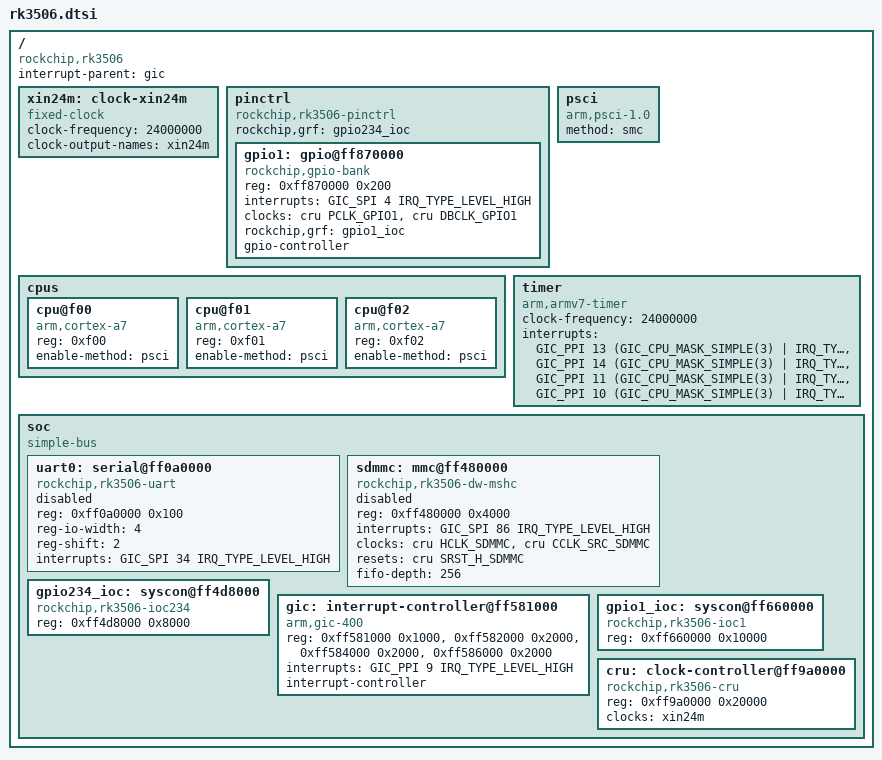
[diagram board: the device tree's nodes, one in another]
// SPDX-License-Identifier: (GPL-2.0+ OR MIT)
/*
 * Rockchip RK3506, Cortex-A7 application processor.
 * Register and interrupt assignments from the Rockchip RK3506 BSP and
 * the RK3506 device tree by Jonas Karlman (linux-rockchip 7e4c7f871924).
 */

#include <dt-bindings/clock/rockchip,rk3506-cru.h>
#include <dt-bindings/interrupt-controller/arm-gic.h>
#include <dt-bindings/reset/rockchip,rk3506-cru.h>

/ {
	#address-cells = <1>;
	#size-cells = <1>;
	compatible = "rockchip,rk3506";
	interrupt-parent = <&gic>;

	xin24m: clock-xin24m {
		compatible = "fixed-clock";
		#clock-cells = <0>;
		clock-frequency = <24000000>;
		clock-output-names = "xin24m";
	};

	pinctrl: pinctrl {
		compatible = "rockchip,rk3506-pinctrl";
		rockchip,grf = <&gpio234_ioc>;
		#address-cells = <1>;
		#size-cells = <1>;
		ranges;

		gpio1: gpio@ff870000 {
			compatible = "rockchip,gpio-bank";
			reg = <0xff870000 0x200>;
			interrupts = <GIC_SPI 4 IRQ_TYPE_LEVEL_HIGH>;
			clocks = <&cru PCLK_GPIO1>, <&cru DBCLK_GPIO1>;
			rockchip,grf = <&gpio1_ioc>;
			gpio-controller;
			#gpio-cells = <2>;
		};
	};

	cpus {
		#address-cells = <1>;
		#size-cells = <0>;

		cpu@f00 {
			device_type = "cpu";
			compatible = "arm,cortex-a7";
			reg = <0xf00>;
			enable-method = "psci";
		};

		cpu@f01 {
			device_type = "cpu";
			compatible = "arm,cortex-a7";
			reg = <0xf01>;
			enable-method = "psci";
		};

		cpu@f02 {
			device_type = "cpu";
			compatible = "arm,cortex-a7";
			reg = <0xf02>;
			enable-method = "psci";
		};
	};

	psci {
		compatible = "arm,psci-1.0", "arm,psci-0.2";
		method = "smc";
	};

	timer {
		compatible = "arm,armv7-timer";
		clock-frequency = <24000000>;
		interrupts = <GIC_PPI 13 (GIC_CPU_MASK_SIMPLE(3) | IRQ_TYPE_LEVEL_HIGH)>,
			     <GIC_PPI 14 (GIC_CPU_MASK_SIMPLE(3) | IRQ_TYPE_LEVEL_HIGH)>,
			     <GIC_PPI 11 (GIC_CPU_MASK_SIMPLE(3) | IRQ_TYPE_LEVEL_HIGH)>,
			     <GIC_PPI 10 (GIC_CPU_MASK_SIMPLE(3) | IRQ_TYPE_LEVEL_HIGH)>;
	};

	soc {
		compatible = "simple-bus";
		#address-cells = <1>;
		#size-cells = <1>;
		ranges;

		uart0: serial@ff0a0000 {
			compatible = "rockchip,rk3506-uart", "snps,dw-apb-uart";
			reg = <0xff0a0000 0x100>;
			reg-io-width = <4>;
			reg-shift = <2>;
			interrupts = <GIC_SPI 34 IRQ_TYPE_LEVEL_HIGH>;
			status = "disabled";
		};

		sdmmc: mmc@ff480000 {
			compatible = "rockchip,rk3506-dw-mshc", "rockchip,rk3288-dw-mshc";
			reg = <0xff480000 0x4000>;
			interrupts = <GIC_SPI 86 IRQ_TYPE_LEVEL_HIGH>;
			clocks = <&cru HCLK_SDMMC>, <&cru CCLK_SRC_SDMMC>;
			clock-names = "biu", "ciu";
			resets = <&cru SRST_H_SDMMC>;
			reset-names = "reset";
			fifo-depth = <256>;
			status = "disabled";
		};

		gpio234_ioc: syscon@ff4d8000 {
			compatible = "rockchip,rk3506-ioc234", "syscon";
			reg = <0xff4d8000 0x8000>;
		};

		gic: interrupt-controller@ff581000 {
			compatible = "arm,gic-400";
			reg = <0xff581000 0x1000>, <0xff582000 0x2000>,
			      <0xff584000 0x2000>, <0xff586000 0x2000>;
			interrupts = <GIC_PPI 9 IRQ_TYPE_LEVEL_HIGH>;
			#address-cells = <0>;
			#interrupt-cells = <3>;
			interrupt-controller;
		};

		gpio1_ioc: syscon@ff660000 {
			compatible = "rockchip,rk3506-ioc1", "syscon";
			reg = <0xff660000 0x10000>;
		};

		cru: clock-controller@ff9a0000 {
			compatible = "rockchip,rk3506-cru";
			reg = <0xff9a0000 0x20000>;
			clocks = <&xin24m>;
			clock-names = "xin";
			#clock-cells = <1>;
			#reset-cells = <1>;
		};
	};
};
